# FPB_356.0 register map
Vendor: Texas Instruments
Peripheral module from a debugger description file (folder MSP432).
Registers are 32-bit, read-write, no defined reset value unless marked. A register's access mark holds for its fields unless they carry their own. Offsets are as the file gives them; lines under a group give offsets from that group; [hi:lo] are bit positions; {n}, {i} and the like mark numbered series; 'fields as' and 'values as' point back to an identical list; <NAME> marks a mode.

## FPB
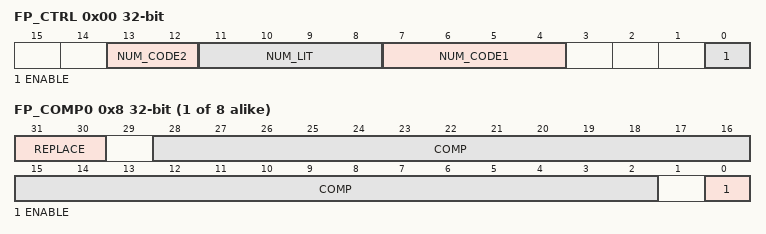
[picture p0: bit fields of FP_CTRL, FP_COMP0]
0x00 FP_CTRL access per field — Flash Patch Control Register
  [13:12] NUM_CODE2 ro — Number of full banks of code comparators, sixteen comparators per bank. Where less than sixteen code comparators are provided, the bank count is zero, and the number present indicated by NUM_CODE. This read only field contains 3'b000 to indicate 0 banks for Cortex-M4 processor.
  [11:8] NUM_LIT ro — Number of literal slots field.
    0=en_0b0000 (no literal slots); 2=en_0b0010 (two literal slots)
  [7:4] NUM_CODE1 ro — Number of code slots field.
    0=en_0b0000 (no code slots); 2=en_0b0010 (two code slots); 6=en_0b0110 (six code slots)
  [0] ENABLE rw — Flash patch unit enable bit
    0=en_0b0 (flash patch unit disabled); 1=en_0b1 (flash patch unit enabled)
0x04 FP_REMAP — Flash Patch Remap Register
  [28:5] REMAP — Remap base address field.
{0x8+4i} FP_COMP{i} (i=0..7) — Flash Patch Comparator Registers
  [31:30] REPLACE — This selects what happens when the COMP address is matched. Settings other than b00 are only valid for instruction comparators. Literal comparators ignore non-b00 settings. Address remapping only takes place for the b00 setting.
    0=en_0b00 (remap to remap address. See FP_REMAP); 1=en_0b01 (set BKPT on lower halfword, upper is unaffected); 2=en_0b10 (set BKPT on upper halfword, lower is unaffected); 3=en_0b11 (set BKPT on both lower and upper halfwords.)
  [28:2] COMP — Comparison address.
  [0] ENABLE — Compare and remap enable for Flash Patch Comparator Register {i}. The ENABLE bit of FP_CTRL must also be set to enable comparisons. Reset clears the ENABLE bit.
    0=en_0b0 (Flash Patch Comparator Register {i} compare and remap disabled); 1=en_0b1 (Flash Patch Comparator Register {i} compare and remap enabled)
